# STM32WL3xx register map
File version: 1.0
Registers are 32-bit, read-write, reset 0x0 unless marked. A register's access mark holds for its fields unless they carry their own. Offsets are from the block's base; [hi:lo] are bit positions; {n}, {i} and the like mark numbered series.

## IWDG — Independent watchdog (IWDG)
Base 0x40003000
0x00 KR — (@ 0x00000000) Key register
  [15:0] KEY
0x04 PR — (@ 0x00000004) Prescaler register
  [2:0] PR
0x08 RLR — (@ 0x00000008) Reload register
  [11:0] RL
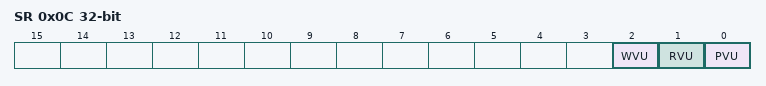
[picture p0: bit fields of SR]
0x0C SR — (@ 0x0000000C) Status register
  [2] WVU, [1] RVU, [0] PVU
0x10 WINR — (@ 0x00000010) Window register
  [11:0] WIN

## TIM16 — Advanced-timers (TIM)
Base 0x40005000
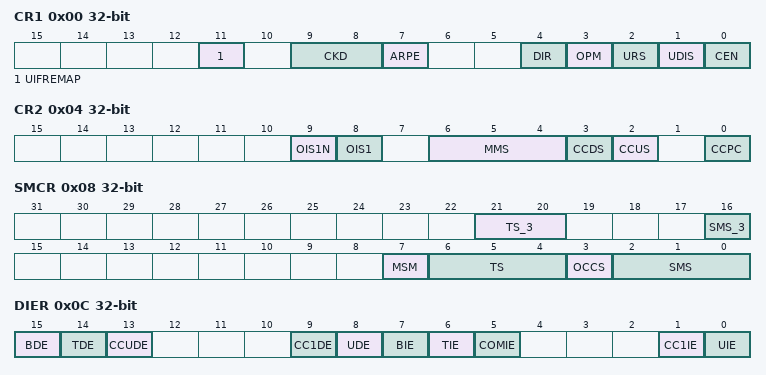
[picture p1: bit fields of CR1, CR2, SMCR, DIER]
0x00 CR1 — (@ 0x00000000) Control register 1
  [11] UIFREMAP
  [9:8] CKD
    0=DIV1 (tDTS=tCK_INT); 1=DIV2 (tDTS=2*tCK_INT); 2=DIV4 (tDTS=4*tCK_INT)
  [7] ARPE
  [4] DIR
    0=UP (Timer counter counts up); 1=DOWN (Timer counter counts down)
  [3] OPM
    1=SINGLE (Counter stops counting at the next update event); 0=REPETITIVE (Counter is not stopped at update event)
  [2] URS
    0=REGULAR (Counter overflow/underflow, Setting the UG bit or Update generation through the slave mode controller generates an update request); 1=COUNTER (Only counter overflow/underflow generates an update request)
  [1] UDIS
  [0] CEN
0x04 CR2 — (@ 0x00000004) Control register 2
  [9] OIS1N
  [8] OIS1
  [6:4] MMS
    0=RESET (UG bit from the TIMx_EGR register is used as trigger output); 1=ENABLE (Counter Enable signal (CNT_EN) is used as trigger output); 2=UPDATE (Update event is used as trigger output); 3=CC1IF (CC1 capture or a compare match is used as trigger output); {v}=OC{v-3}REF (OC{v-3}REF signal is used as trigger output) (v=4..7)
  [3] CCDS
    0=CC (CCx DMA request sent when CCx event occurs); 1=UPDATE (CCx DMA requests sent when update event occurs)
  [2] CCUS
    0=ONLY (Capture/compare control bits are updated by setting the COMG bit only); 1=AND_TRGI (Capture/compare control bits are updated by setting the COMG bit or when a rising edge occurs on trigger input (TRGI))
  [0] CCPC
0x08 SMCR — (@ 0x00000008) Slave mode control register
  [21:20] TS_3
  [16] SMS_3
  [7] MSM
  [6:4] TS
  [3] OCCS
    0=OCREF_CLR (OCREF_CLR_INT is connected to the OCREF_CLR input); 1=ETR (OCREF_CLR_INT is connected to ETRF)
  [2:0] SMS
0x0C DIER — (@ 0x0000000C) DMA/Interrupt enable register
  [15] BDE, [14] TDE, [13] CCUDE, [9] CC1DE, [8] UDE, [7] BIE, [6] TIE, [5] COMIE, [1] CC1IE, [0] UIE
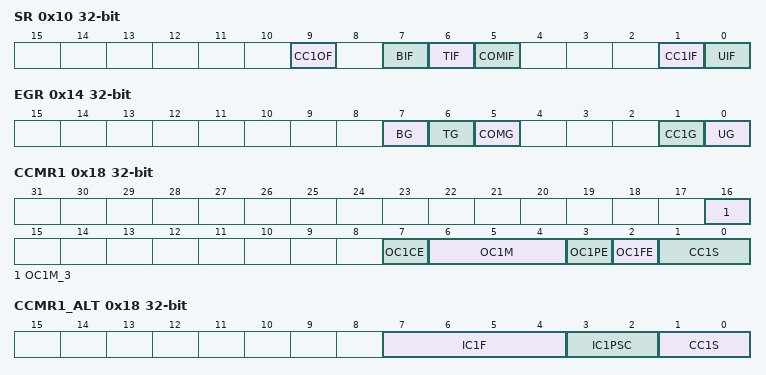
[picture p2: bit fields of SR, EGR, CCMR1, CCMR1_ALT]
0x10 SR — (@ 0x00000010) Status register
  [9] CC1OF, [7] BIF, [6] TIF, [5] COMIF, [1] CC1IF, [0] UIF
0x14 EGR — (@ 0x00000014) Event generation register
  [7] BG, [6] TG, [5] COMG, [1] CC1G, [0] UG
0x18 CCMR1 — (@ 0x00000018) Input capture and output compare mode register 1
  [16] OC1M_3, [7] OC1CE, [6:4] OC1M, [3] OC1PE, [2] OC1FE, [1:0] CC1S
0x18 CCMR1_ALT (alternate view of CCMR1) — (@ 0x00000018) Input capture and output compare mode register 1
  [7:4] IC1F, [3:2] IC1PSC, [1:0] CC1S
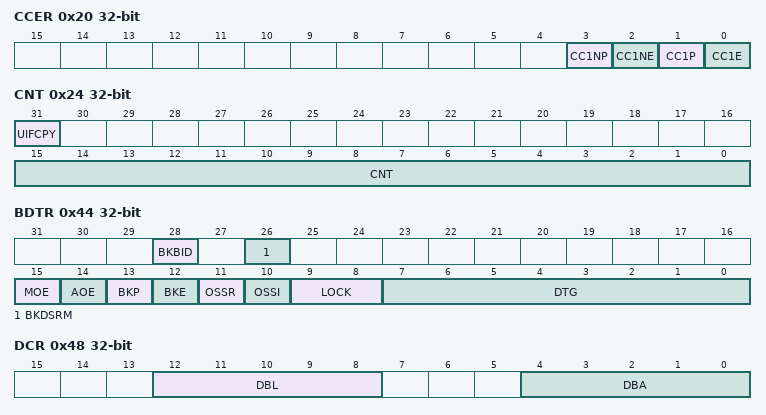
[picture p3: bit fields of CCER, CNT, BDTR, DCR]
0x20 CCER — (@ 0x00000020) Capture/compare enable register
  [3] CC1NP, [2] CC1NE, [1] CC1P, [0] CC1E
0x24 CNT — (@ 0x00000024) Counter
  [31] UIFCPY, [15:0] CNT
0x28 PSC — (@ 0x00000028) Prescaler
  [15:0] PSC
0x2C ARR — (@ 0x0000002C) Auto-reload register
  [15:0] ARR
0x30 RCR — (@ 0x00000030) Repetition counter register
  [7:0] REP
0x34 CCR1 — (@ 0x00000034) Capture/compare register 1
  [15:0] CCR1
0x44 BDTR — (@ 0x00000044) Break and dead-time register
  [28] BKBID
  [26] BKDSRM
  [15] MOE
  [14] AOE
  [13] BKP
  [12] BKE
  [11] OSSR
  [10] OSSI
  [9:8] LOCK
    0=OFF (LOCK OFF - No bit is write protected); 1=LOCKLEVEL_1; 2=LOCKLEVEL_2; 3=LOCKLEVEL_3
  [7:0] DTG
0x48 DCR — (@ 0x00000048) DMA control register
  [12:8] DBL, [4:0] DBA
0x4C DMAR — (@ 0x0000004C) DMA address for full transfer
  [15:0] DMAB
0x50 OR — (@ 0x00000050) Option register 1
  [2:1] TI1_RMP — Timer 16 input 1 connection
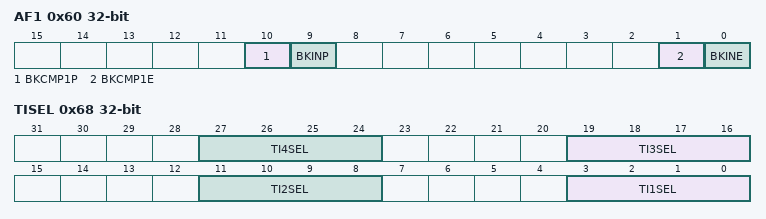
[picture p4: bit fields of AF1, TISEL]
0x60 AF1 — (@ 0x00000060) TIM alternate function option register 1
  [10] BKCMP1P, [9] BKINP, [1] BKCMP1E, [0] BKINE
0x68 TISEL — (@ 0x00000068) Input selection register
  [8n-5:8n-8] TI{n}SEL (n=1..4)
